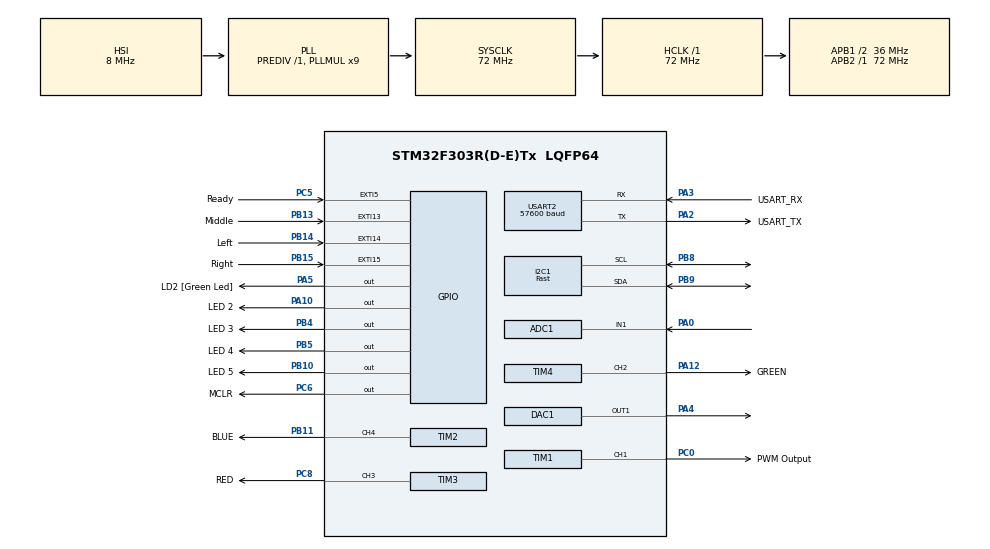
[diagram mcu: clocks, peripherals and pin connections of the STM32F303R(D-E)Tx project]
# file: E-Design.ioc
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ADC1.Channel-1\#ChannelRegularConversion=ADC_CHANNEL_1
ADC1.ContinuousConvMode=ENABLE
ADC1.NbrOfConversionFlag=1
ADC1.Offset-1\#ChannelRegularConversion=0
ADC1.OffsetNumber-1\#ChannelRegularConversion=ADC_OFFSET_NONE
ADC1.Rank-1\#ChannelRegularConversion=1
ADC1.SamplingTime-1\#ChannelRegularConversion=ADC_SAMPLETIME_1CYCLE_5
ADC1.SamplingTimeOPAMP-1\#ChannelRegularConversion=ADC_SAMPLETIME_61CYCLES_5
ADC1.master=1
DAC1.DAC_OutputBuffer=DAC_OUTPUTBUFFER_ENABLE
Dma.Request0=TIM1_CH1
Dma.TIM1_CH1.0.Direction=DMA_MEMORY_TO_PERIPH
Dma.TIM1_CH1.0.Instance=DMA1_Channel2
Dma.TIM1_CH1.0.MemDataAlignment=DMA_MDATAALIGN_HALFWORD
Dma.TIM1_CH1.0.MemInc=DMA_MINC_ENABLE
Dma.TIM1_CH1.0.Mode=DMA_NORMAL
Dma.TIM1_CH1.0.PeriphDataAlignment=DMA_PDATAALIGN_HALFWORD
Dma.TIM1_CH1.0.PeriphInc=DMA_PINC_DISABLE
Dma.TIM1_CH1.0.Priority=DMA_PRIORITY_LOW
I2C1.I2C_Speed_Mode=I2C_Fast
I2C1.Timing=0x0000020B
Mcu.Family=STM32F3
Mcu.Name=STM32F303R(D-E)Tx
Mcu.Package=LQFP64
NVIC.DMA1_Channel2_IRQn=true\:0\:0\:false\:false\:true\:false\:true\:true
NVIC.EXTI15_10_IRQn=true\:0\:0\:false\:false\:true\:true\:true\:true
NVIC.EXTI9_5_IRQn=true\:0\:0\:false\:false\:true\:true\:true\:true
NVIC.PriorityGroup=NVIC_PRIORITYGROUP_0
NVIC.TIM1_TRG_COM_TIM17_IRQn=true\:0\:0\:false\:false\:true\:true\:true\:true
NVIC.TIM1_UP_TIM16_IRQn=true\:0\:0\:false\:false\:true\:true\:true\:true
NVIC.USART2_IRQn=true\:0\:0\:false\:false\:true\:true\:true\:true
PA0.Mode=IN1-Single-Ended
PA0.Signal=ADC1_IN1
PA10.GPIO_Label=LED 2
PA10.Signal=GPIO_Output
PA12.GPIO_Label=GREEN
PA12.Signal=S_TIM4_CH2
PA13.GPIO_Label=TMS
PA13.Mode=Serial_Wire
PA13.Signal=SYS_JTMS-SWDIO
PA14.GPIO_Label=TCK
PA14.Mode=Serial_Wire
PA14.Signal=SYS_JTCK-SWCLK
PA2.GPIO_Label=USART_TX
PA2.GPIO_Mode=GPIO_MODE_AF_PP
PA2.GPIO_PuPd=GPIO_NOPULL
PA2.GPIO_Speed=GPIO_SPEED_FREQ_LOW
PA2.Mode=Asynchronous
PA2.Signal=USART2_TX
PA3.GPIO_Label=USART_RX
PA3.GPIO_Mode=GPIO_MODE_AF_PP
PA3.GPIO_PuPd=GPIO_NOPULL
PA3.GPIO_Speed=GPIO_SPEED_FREQ_LOW
PA3.Mode=Asynchronous
PA3.Signal=USART2_RX
PA4.Signal=COMP_DAC11_group
PA5.GPIO_Label=LD2 [Green Led]
PA5.GPIO_Mode=GPIO_MODE_OUTPUT_PP
PA5.GPIO_PuPd=GPIO_NOPULL
PA5.GPIO_Speed=GPIO_SPEED_FREQ_LOW
PA5.Signal=GPIO_Output
PB10.GPIO_Label=LED 5
PB10.Signal=GPIO_Output
PB11.GPIO_Label=BLUE
PB11.Signal=S_TIM2_CH4
PB13.GPIO_Label=Middle
PB13.GPIO_ModeDefaultEXTI=GPIO_MODE_IT_RISING_FALLING
PB13.GPIO_PuPd=GPIO_PULLUP
PB13.Signal=GPXTI13
PB14.GPIO_Label=Left
PB14.GPIO_ModeDefaultEXTI=GPIO_MODE_IT_RISING_FALLING
PB14.GPIO_PuPd=GPIO_PULLUP
PB14.Signal=GPXTI14
PB15.GPIO_Label=Right
PB15.GPIO_ModeDefaultEXTI=GPIO_MODE_IT_RISING_FALLING
PB15.GPIO_PuPd=GPIO_PULLUP
PB15.Signal=GPXTI15
PB3.GPIO_Label=SWO
PB3.Signal=SYS_JTDO-TRACESWO
PB4.GPIO_Label=LED 3
PB4.Signal=GPIO_Output
PB5.GPIO_Label=LED 4
PB5.Signal=GPIO_Output
PB8.GPIO_Pu=GPIO_PULLUP
PB8.Mode=I2C
PB8.Signal=I2C1_SCL
PB9.GPIO_Pu=GPIO_PULLUP
PB9.Mode=I2C
PB9.Signal=I2C1_SDA
PC0.GPIO_Label=PWM Output
PC0.Signal=S_TIM1_CH1
PC14-OSC32_IN.Mode=LSE-External-Oscillator
PC14-OSC32_IN.Signal=RCC_OSC32_IN
PC15-OSC32_OUT.Mode=LSE-External-Oscillator
PC15-OSC32_OUT.Signal=RCC_OSC32_OUT
PC5.GPIO_Label=Ready
PC5.GPIO_ModeDefaultEXTI=GPIO_MODE_IT_FALLING
PC5.GPIO_PuPd=GPIO_PULLUP
PC5.Signal=GPXTI5
PC6.GPIO_Label=MCLR
PC6.Signal=GPIO_Output
PC8.GPIO_Label=RED
PC8.Signal=S_TIM3_CH3
PF0-OSC_IN.Mode=HSE-External-Oscillator
PF0-OSC_IN.Signal=RCC_OSC_IN
PF1-OSC_OUT.Mode=HSE-External-Oscillator
PF1-OSC_OUT.Signal=RCC_OSC_OUT
ProjectManager.HeapSize=0x200
ProjectManager.StackSize=0x400
ProjectManager.TargetToolchain=STM32CubeIDE
RCC.AHBFreq_Value=72000000
RCC.APB1CLKDivider=RCC_HCLK_DIV2
RCC.APB1Freq_Value=36000000
RCC.APB1TimFreq_Value=72000000
RCC.APB2Freq_Value=72000000
RCC.APB2TimFreq_Value=72000000
RCC.CortexFreq_Value=72000000
RCC.HCLKFreq_Value=72000000
RCC.HSE_VALUE=8000000
RCC.HSI_VALUE=8000000
RCC.PLLM=8
RCC.PLLMUL=RCC_PLL_MUL9
RCC.PLLN=336
RCC.PLLP=RCC_PLLP_DIV4
RCC.PLLQ=7
RCC.RCC_PLLsource_Clock_Source_FROM_HSE=RCC_HSE_PREDIV_DIV2
RCC.SYSCLKFreq_VALUE=72000000
RCC.SYSCLKSourceVirtual=RCC_SYSCLKSOURCE_PLLCLK
RCC.USBFreq_Value=72000000
SH.COMP_DAC11_group.0=DAC1_OUT1,DAC_OUT1
SH.S_TIM1_CH1.0=TIM1_CH1,PWM Generation1 CH1
SH.S_TIM2_CH4.0=TIM2_CH4,PWM Generation4 CH4
SH.S_TIM3_CH3.0=TIM3_CH3,PWM Generation3 CH3
SH.S_TIM4_CH2.0=TIM4_CH2,PWM Generation2 CH2
TIM1.Channel-PWM\ Generation1\ CH1=TIM_CHANNEL_1
TIM1.Period=511
TIM1.Prescaler=13
TIM16.Period=9-1
TIM16.Prescaler=8000-1
TIM17.Period=4609-1
TIM17.Prescaler=8000-1
TIM2.Channel-PWM\ Generation4\ CH4=TIM_CHANNEL_4
TIM2.Period=511
TIM2.Prescaler=8
TIM3.Channel-PWM\ Generation3\ CH3=TIM_CHANNEL_3
TIM3.Period=511
TIM3.Prescaler=8
TIM4.Channel-PWM\ Generation2\ CH2=TIM_CHANNEL_2
TIM4.Period=511
TIM4.Prescaler=8
USART2.BaudRate=57600
USART2.Parity=PARITY_EVEN
USART2.StopBits=STOPBITS_2
USART2.VirtualMode-Asynchronous=VM_ASYNC
USART2.WordLength=WORDLENGTH_9B
VP_TIM16_VS_ClockSourceINT.Mode=Enable_Timer
VP_TIM17_VS_ClockSourceINT.Mode=Enable_Timer
VP_TIM1_VS_ClockSourceINT.Mode=Internal
board=NUCLEO-F303RE

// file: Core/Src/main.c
/* USER CODE BEGIN Header */
/**
  ******************************************************************************
  * @file           : main.c
  * @brief          : Main program body
  ******************************************************************************
  * @attention
  *
  * Copyright (c) 2023 STMicroelectronics.
  * All rights reserved.
  *
  * This software is licensed under terms that can be found in the LICENSE file
  * in the root directory of this software component.
  * If no LICENSE file comes with this software, it is provided AS-IS.
  *
  ******************************************************************************
  */
/* USER CODE END Header */
#include "main.h"
#include "adc.h"
#include "dac.h"
#include "dma.h"
#include "i2c.h"
#include "tim.h"
#include "usart.h"
#include "gpio.h"

/* USER CODE BEGIN Includes */
#include "SystemStates.h"
#include "stdio.h"
#include "Functions.h"
#include "String.h"
#include "TrackPad.h"
#include "iqs7211a_addresses.h"

/* USER CODE END Includes */

/* USER CODE BEGIN PV */

extern uint32_t slider_value, prev_slider_value;
extern uint16_t Light_Intensity;

uint16_t Red_Intensity,Green_Intensity,Blue_Intensity;

char RxCharacter;

/* USER CODE END PV */

void SystemClock_Config(void);

int main(void)
{

  /* MCU Configuration--------------------------------------------------------*/

  /* Reset of all peripherals, Initializes the Flash interface and the Systick. */
  HAL_Init();

  /* Configure the system clock */
  SystemClock_Config();

  /* Initialize all configured peripherals */
  MX_GPIO_Init();
  MX_DMA_Init();
  MX_USART2_UART_Init();
  MX_ADC1_Init();
  MX_DAC1_Init();
  MX_TIM1_Init();
  MX_TIM16_Init();
  MX_TIM17_Init();
  MX_I2C1_Init();
  MX_TIM2_Init();
  MX_TIM3_Init();
  MX_TIM4_Init();
  /* USER CODE BEGIN 2 */

  Setup();//Calls the setup function for first time setup
  TrackPadSetup();//Setups up the track pad for gesture control
  SystemRefresh();

  /* USER CODE END 2 */

  /* Infinite loop */
  while (1)
  {

    /* USER CODE BEGIN 3 */
	  Slider_Update();

  }
  /* USER CODE END 3 */
}

void SystemClock_Config(void)
{
  RCC_OscInitTypeDef RCC_OscInitStruct = {0};
  RCC_ClkInitTypeDef RCC_ClkInitStruct = {0};
  RCC_PeriphCLKInitTypeDef PeriphClkInit = {0};

  /** Initializes the RCC Oscillators according to the specified parameters
  * in the RCC_OscInitTypeDef structure.
  */
  RCC_OscInitStruct.OscillatorType = RCC_OSCILLATORTYPE_HSI;
  RCC_OscInitStruct.HSIState = RCC_HSI_ON;
  RCC_OscInitStruct.HSICalibrationValue = RCC_HSICALIBRATION_DEFAULT;
  RCC_OscInitStruct.PLL.PLLState = RCC_PLL_ON;
  RCC_OscInitStruct.PLL.PLLSource = RCC_PLLSOURCE_HSI;
  RCC_OscInitStruct.PLL.PLLMUL = RCC_PLL_MUL9;
  RCC_OscInitStruct.PLL.PREDIV = RCC_PREDIV_DIV1;
  if (HAL_RCC_OscConfig(&RCC_OscInitStruct) != HAL_OK)
  {
    Error_Handler();
  }

  /** Initializes the CPU, AHB and APB buses clocks
  */
  RCC_ClkInitStruct.ClockType = RCC_CLOCKTYPE_HCLK|RCC_CLOCKTYPE_SYSCLK
                              |RCC_CLOCKTYPE_PCLK1|RCC_CLOCKTYPE_PCLK2;
  RCC_ClkInitStruct.SYSCLKSource = RCC_SYSCLKSOURCE_PLLCLK;
  RCC_ClkInitStruct.AHBCLKDivider = RCC_SYSCLK_DIV1;
  RCC_ClkInitStruct.APB1CLKDivider = RCC_HCLK_DIV2;
  RCC_ClkInitStruct.APB2CLKDivider = RCC_HCLK_DIV1;

  if (HAL_RCC_ClockConfig(&RCC_ClkInitStruct, FLASH_LATENCY_2) != HAL_OK)
  {
    Error_Handler();
  }
  PeriphClkInit.PeriphClockSelection = RCC_PERIPHCLK_USART2|RCC_PERIPHCLK_I2C1
                              |RCC_PERIPHCLK_TIM1|RCC_PERIPHCLK_TIM16
                              |RCC_PERIPHCLK_TIM17|RCC_PERIPHCLK_ADC12
                              |RCC_PERIPHCLK_TIM2|RCC_PERIPHCLK_TIM34;
  PeriphClkInit.Usart2ClockSelection = RCC_USART2CLKSOURCE_PCLK1;
  PeriphClkInit.Adc12ClockSelection = RCC_ADC12PLLCLK_DIV1;
  PeriphClkInit.I2c1ClockSelection = RCC_I2C1CLKSOURCE_HSI;
  PeriphClkInit.Tim1ClockSelection = RCC_TIM1CLK_HCLK;
  PeriphClkInit.Tim16ClockSelection = RCC_TIM16CLK_HCLK;
  PeriphClkInit.Tim17ClockSelection = RCC_TIM17CLK_HCLK;
  PeriphClkInit.Tim2ClockSelection = RCC_TIM2CLK_HCLK;
  PeriphClkInit.Tim34ClockSelection = RCC_TIM34CLK_HCLK;
  if (HAL_RCCEx_PeriphCLKConfig(&PeriphClkInit) != HAL_OK)
  {
    Error_Handler();
  }
}

void Error_Handler(void)
{
  /* USER CODE BEGIN Error_Handler_Debug */
  /* User can add his own implementation to report the HAL error return state */
  __disable_irq();
  while (1)
  {
	  //:)
  }
  /* USER CODE END Error_Handler_Debug */
}
